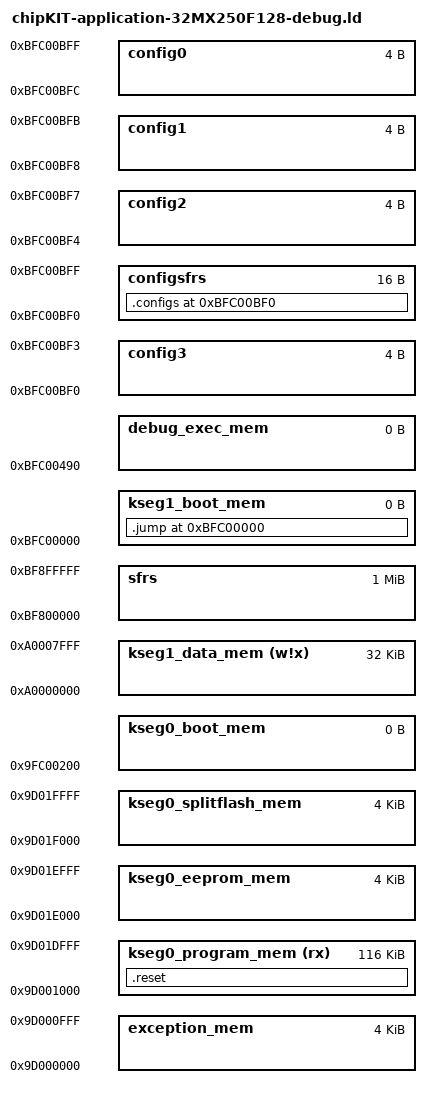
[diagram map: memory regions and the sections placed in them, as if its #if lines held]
/* Default linker script, for normal executables */
OUTPUT_FORMAT("elf32-tradlittlemips")
OUTPUT_ARCH(pic32mx)
ENTRY(_reset)
/*
 * Provide for a minimum stack and heap size
 * - _min_stack_size - represents the minimum space that must be made
 *                     available for the stack.  Can be overridden from
 *                     the command line using the linker's --defsym option.
 * - _min_heap_size  - represents the minimum space that must be made
 *                     available for the heap.  Can be overridden from
 *                     the command line using the linker's --defsym option.
 */
EXTERN (_min_stack_size _min_heap_size)
PROVIDE(_min_stack_size = 0x800) ;
PROVIDE(_min_heap_size = 0x800) ;

/*************************************************************************
 * Processor-specific object file.  Contains SFR definitions.
 *************************************************************************/
INPUT("processor.o")
OPTIONAL("libmchp_peripheral_32MX250F128D.a") 

/*************************************************************************
 * Memory Regions
 *
 * Memory regions without attributes cannot be used for orphaned sections.
 * Only sections specifically assigned to these regions can be allocated
 * into these regions.
 *************************************************************************/
MEMORY
{
  exception_mem              : ORIGIN = 0x9D000000, LENGTH = 0x1000
  kseg0_program_mem    (rx)  : ORIGIN = 0x9D001000, LENGTH = 0x1D000
  kseg0_eeprom_mem           : ORIGIN = 0x9D01E000, LENGTH = 0x1000
  kseg0_splitflash_mem       : ORIGIN = 0x9D01F000, LENGTH = 0x1000
  kseg0_boot_mem             : ORIGIN = 0x9FC00200, LENGTH = 0
  kseg1_boot_mem             : ORIGIN = 0xBFC00000, LENGTH = 0 
  debug_exec_mem             : ORIGIN = 0xBFC00490, LENGTH = 0
  config3                    : ORIGIN = 0xBFC00BF0, LENGTH = 0x4
  config2                    : ORIGIN = 0xBFC00BF4, LENGTH = 0x4
  config1                    : ORIGIN = 0xBFC00BF8, LENGTH = 0x4
  config0                    : ORIGIN = 0xBFC00BFC, LENGTH = 0x4
  kseg1_data_mem       (w!x) : ORIGIN = 0xA0000000, LENGTH = 0x8000
  sfrs                       : ORIGIN = 0xBF800000, LENGTH = 0x100000
  configsfrs                 : ORIGIN = 0xBFC00BF0, LENGTH = 0x10
}

/*************************************************************************
 * Memory Address Equates
 *************************************************************************/
_ebase_address  	    = ORIGIN(exception_mem);
_IMAGE_PTR_TABLE       	= _ebase_address + 0x0F8;
_IMAGE_HEADER_ADDR      = _ebase_address + 0x0FC;
_GEN_EXCPT_ADDR         = _ebase_address + 0x180;
_RESET_ADDR             = ORIGIN(kseg0_program_mem);
_EEPROM_ADDR            = ORIGIN(kseg0_eeprom_mem);
_BEV_EXCPT_ADDR         = 0xBFC00380;
_DBG_EXCPT_ADDR         = 0xBFC00480;
_DBG_CODE_ADDR          = ORIGIN(debug_exec_mem);

/*************************************************************************
 *  Bootloader program directives.
 *  
 * _IMAGE_TYPE
 *
 *  image type:
 */
     
_imageReserved                      = 0x00000000 ;
_imageMPIDE                         = 0x00000001 ;  /* This is a normal MPIDE sketch                                                                                                    */
_imageBootFlashBootloader           = 0x00000002 ;  /* This is a boot flash bootloader                                                                                                  */
_imageProgramFlashBootloader        = 0x00000004 ;  /* This is a program flash bootloader                                                                                               */
_imageSplitFlashBootloader          = 0x00000008 ;  /* This has bootloader code in both boot and program flash                                                                          */

 /*
 *  Instructions for the bootloader
 */
                                                                       
_imageFullFlashEraseLess4KEEProm    = 0x00010000 ;  /* The original bootloader method of erasing all of program flash except the last 4K reserved for eeprom                            */
_imageJustInTimeFlashErase          = 0x00020000 ;  /* Only flash pages written too needed by the sketch is erased                                                                      */
_imageLinkerSpecifiedFlashErase     = 0x00040000 ;  /* The linker defines the flash range to erase                                                                                      */
_imageFullFlashErase                = 0x00080000 ;  /* All of flash is erased                                                                                                           */
_imageExecutionJumpAddress          = 0x01000000 ;  /* the bootloader will jump to the execution jump address immediately after programming                                             */
_imageExecutionJumpToFirstInFlash   = 0x02000000 ;  /* the bootloader will jump to the first sketch loaded in flash ignoring the execution jump address immediately after programming   */
 
/*  
 * _IMAGE_FLASH_SIZE 
 *
 *      Typically _imageJustInTimeFlashErase is selected to just erase the pages
 *      of flash that code is written too; thus leaving all other flash pages untouched.
 *  
 *      If _imageLinkerSpecifiedFlashErase set, then the range
 *      starting from _ebase_address for _IMAGE_FLASH_SIZE bytes are erased.
 *
 *      If _imageFullFlashErase is specified, than the whole flash
 *      as known by the bootloader will be erased. This will erase eeprom as well
 *
 *      if _imageFullFlashEraseLess4KEEProm is set, all of flash less the last 4K is
 *      erased, this is the old default. This bit could be set to make a program flash bootloader
 *      erasing everything but the old flash. If NOTHING is set, this will be the default as this is the old behavior.
 *  
 *  _JUMP_ADDR
 *  
 *      This is the address that the bootloader will jump to start execution
 *      of the sketch. This is almost always _RESET_ADDR.
 *
 *      However, you can specify an alternate entry execution point for example
 *      if you have alternate starup code that, say, shared
 *      the runtime with other sketches or needed some kind of specific handling
 *
 *      Immediately after programming (avrdude upload) the bootloader will typically
 *      jump to the just loaded sketch, no matter where it was loaded in flash.
 *      _imageExecutionJumpToFirstInFlash will tell the bootloader to jump to the first
 *      sketch in flash even if the just loaded one is not at the beginning of flash.
 *      This is useful when programming sketches in slots of flash and then always
 *      jumping to the program-flash loader (vector sketch) as if the board was just reset.
 *      This bit does not effect jumping to a sketch already in flash after reset.
 *      As of today, after reset, the first program in flash will always be jumped to.
 *
 *************************************************************************/
 _IMAGE_TYPE            = _imageMPIDE | _imageJustInTimeFlashErase | _imageExecutionJumpAddress;
 _IMAGE_FLASH_SIZE      = LENGTH(exception_mem) + LENGTH(kseg0_program_mem);
_JUMP_ADDR              = _RESET_ADDR;

SECTIONS
{
#if defined(__DEBUG_D)
  /* Jump from reset vector */
  .jump ORIGIN(kseg1_boot_mem): {
    LONG(0x3C1F9D00)  /* lui ra 0x9d00 */
    LONG(0x37FF1000)  /* ori ra 0x1000 */
    LONG(0x03E00008)  /* jr ra */
    LONG(0x00000000)  /* nop */
  } > kseg1_boot_mem
#else
  /* Insert bootloader */
  .jump ORIGIN(kseg1_boot_mem): {
    LONG(0x401A6000)	/* 0x1FC00000 */
    LONG(0x7F5A04C0)	/* 0x1FC00004 */
    LONG(0x13400006)	/* 0x1FC00008 */
    LONG(0x401A6000)	/* 0x1FC0000C */
    LONG(0x3C1BFFBF)	/* 0x1FC00010 */
    LONG(0x377BFFFF)	/* 0x1FC00014 */
    LONG(0x35BD024)		/* 0x1FC00018 */
    LONG(0x409A6000)	/* 0x1FC0001C */
    LONG(0x42000018)	/* 0x1FC00020 */
    LONG(0x3C1DA000)	/* 0x1FC00024 */
    LONG(0x27BD3FF8)	/* 0x1FC00028 */
    LONG(0x3C1CA001)	/* 0x1FC0002C */
    LONG(0x279C85F0)	/* 0x1FC00030 */
    LONG(0x40096002)	/* 0x1FC00034 */
    LONG(0x1205820)		/* 0x1FC00038 */
    LONG(0x7D2A1E80)	/* 0x1FC0003C */
    LONG(0x7D494984)	/* 0x1FC00040 */
    LONG(0x40896002)	/* 0x1FC00044 */
    LONG(0xC0)			/* 0x1FC00048 */
    LONG(0x41DCE000)	/* 0x1FC0004C */
    LONG(0x408B6002)	/* 0x1FC00050 */
    LONG(0x3C08A000)	/* 0x1FC00054 */
    LONG(0x25080628)	/* 0x1FC00058 */
    LONG(0x3C09A000)	/* 0x1FC0005C */
    LONG(0x25290840)	/* 0x1FC00060 */
    LONG(0x10000006)	/* 0x1FC00064 */
    LONG(0x0)			/* 0x1FC00068 */
    LONG(0xAD000000)	/* 0x1FC0006C */
    LONG(0xAD000004)	/* 0x1FC00070 */
    LONG(0xAD000008)	/* 0x1FC00074 */
    LONG(0xAD00000C)	/* 0x1FC00078 */
    LONG(0x25080010)	/* 0x1FC0007C */
    LONG(0x109082B)		/* 0x1FC00080 */
    LONG(0x1420FFF9)	/* 0x1FC00084 */
    LONG(0x0)			/* 0x1FC00088 */
    LONG(0x3C089FC0)	/* 0x1FC0008C */
    LONG(0x25080A84)	/* 0x1FC00090 */
    LONG(0x8D090000)	/* 0x1FC00094 */
    LONG(0x11200018)	/* 0x1FC00098 */
    LONG(0x25080004)	/* 0x1FC0009C */
    LONG(0x8D0A0000)	/* 0x1FC000A0 */
    LONG(0x25080004)	/* 0x1FC000A4 */
    LONG(0x8D0B0000)	/* 0x1FC000A8 */
    LONG(0x11600009)	/* 0x1FC000AC */
    LONG(0x25080004)	/* 0x1FC000B0 */
    LONG(0x910C0000)	/* 0x1FC000B4 */
    LONG(0x254AFFFF)	/* 0x1FC000B8 */
    LONG(0x25080001)	/* 0x1FC000BC */
    LONG(0xA12C0000)	/* 0x1FC000C0 */
    LONG(0x1540FFFB)	/* 0x1FC000C4 */
    LONG(0x25290001)	/* 0x1FC000C8 */
    LONG(0x10000005)	/* 0x1FC000CC */
    LONG(0x0)			/* 0x1FC000D0 */
    LONG(0xA1200000)	/* 0x1FC000D4 */
    LONG(0x254AFFFF)	/* 0x1FC000D8 */
    LONG(0x1540FFFD)	/* 0x1FC000DC */
    LONG(0x25290001)	/* 0x1FC000E0 */
    LONG(0x25080003)	/* 0x1FC000E4 */
    LONG(0x240AFFFC)	/* 0x1FC000E8 */
    LONG(0x1484024)		/* 0x1FC000EC */
    LONG(0x8D090000)	/* 0x1FC000F0 */
    LONG(0x1520FFE7)	/* 0x1FC000F4 */
    LONG(0x0)			/* 0x1FC000F8 */
    LONG(0x3C09BFC0)	/* 0x1FC000FC */
    LONG(0x25290000)	/* 0x1FC00100 */
    LONG(0x40897801)	/* 0x1FC00104 */
    LONG(0x30840000)	/* 0x1FC00108 */
    LONG(0x30A50000)	/* 0x1FC0010C */
    LONG(0x3C089FC0)	/* 0x1FC00110 */
    LONG(0x25080BB8)	/* 0x1FC00114 */
    LONG(0x1000008)		/* 0x1FC00118 */
    LONG(0x0)			/* 0x1FC0011C */
    LONG(0xFFFFFFFF)	/* 0x1FC00120 */
    LONG(0xFFFFFFFF)	/* 0x1FC00124 */
    LONG(0xFFFFFFFF)	/* 0x1FC00128 */
    LONG(0xFFFFFFFF)	/* 0x1FC0012C */
    LONG(0xFFFFFFFF)	/* 0x1FC00130 */
    LONG(0xFFFFFFFF)	/* 0x1FC00134 */
    LONG(0xFFFFFFFF)	/* 0x1FC00138 */
    LONG(0xFFFFFFFF)	/* 0x1FC0013C */
    LONG(0xFFFFFFFF)	/* 0x1FC00140 */
    LONG(0xFFFFFFFF)	/* 0x1FC00144 */
    LONG(0xFFFFFFFF)	/* 0x1FC00148 */
    LONG(0xFFFFFFFF)	/* 0x1FC0014C */
    LONG(0xFFFFFFFF)	/* 0x1FC00150 */
    LONG(0xFFFFFFFF)	/* 0x1FC00154 */
    LONG(0xFFFFFFFF)	/* 0x1FC00158 */
    LONG(0xFFFFFFFF)	/* 0x1FC0015C */
    LONG(0xFFFFFFFF)	/* 0x1FC00160 */
    LONG(0xFFFFFFFF)	/* 0x1FC00164 */
    LONG(0xFFFFFFFF)	/* 0x1FC00168 */
    LONG(0xFFFFFFFF)	/* 0x1FC0016C */
    LONG(0xFFFFFFFF)	/* 0x1FC00170 */
    LONG(0xFFFFFFFF)	/* 0x1FC00174 */
    LONG(0xFFFFFFFF)	/* 0x1FC00178 */
    LONG(0xFFFFFFFF)	/* 0x1FC0017C */
    LONG(0xFFFFFFFF)	/* 0x1FC00180 */
    LONG(0xFFFFFFFF)	/* 0x1FC00184 */
    LONG(0xFFFFFFFF)	/* 0x1FC00188 */
    LONG(0xFFFFFFFF)	/* 0x1FC0018C */
    LONG(0xFFFFFFFF)	/* 0x1FC00190 */
    LONG(0xFFFFFFFF)	/* 0x1FC00194 */
    LONG(0xFFFFFFFF)	/* 0x1FC00198 */
    LONG(0xFFFFFFFF)	/* 0x1FC0019C */
    LONG(0xFFFFFFFF)	/* 0x1FC001A0 */
    LONG(0xFFFFFFFF)	/* 0x1FC001A4 */
    LONG(0xFFFFFFFF)	/* 0x1FC001A8 */
    LONG(0xFFFFFFFF)	/* 0x1FC001AC */
    LONG(0xFFFFFFFF)	/* 0x1FC001B0 */
    LONG(0xFFFFFFFF)	/* 0x1FC001B4 */
    LONG(0xFFFFFFFF)	/* 0x1FC001B8 */
    LONG(0xFFFFFFFF)	/* 0x1FC001BC */
    LONG(0xFFFFFFFF)	/* 0x1FC001C0 */
    LONG(0xFFFFFFFF)	/* 0x1FC001C4 */
    LONG(0xFFFFFFFF)	/* 0x1FC001C8 */
    LONG(0xFFFFFFFF)	/* 0x1FC001CC */
    LONG(0xFFFFFFFF)	/* 0x1FC001D0 */
    LONG(0xFFFFFFFF)	/* 0x1FC001D4 */
    LONG(0xFFFFFFFF)	/* 0x1FC001D8 */
    LONG(0xFFFFFFFF)	/* 0x1FC001DC */
    LONG(0xFFFFFFFF)	/* 0x1FC001E0 */
    LONG(0xFFFFFFFF)	/* 0x1FC001E4 */
    LONG(0xFFFFFFFF)	/* 0x1FC001E8 */
    LONG(0xFFFFFFFF)	/* 0x1FC001EC */
    LONG(0xFFFFFFFF)	/* 0x1FC001F0 */
    LONG(0xFFFFFFFF)	/* 0x1FC001F4 */
    LONG(0xFFFFFFFF)	/* 0x1FC001F8 */
    LONG(0xFFFFFFFF)	/* 0x1FC001FC */
    LONG(0x444CF0F0)	/* 0x1FC00200 */
    LONG(0x44A0F100)	/* 0x1FC00204 */
    LONG(0xEBA3B30D)	/* 0x1FC00208 */
    LONG(0x9A406115)	/* 0x1FC0020C */
    LONG(0x251242A1)	/* 0x1FC00210 */
    LONG(0xED4C6D03)	/* 0x1FC00214 */
    LONG(0x42A72D0F)	/* 0x1FC00218 */
    LONG(0xEBA34D39)	/* 0x1FC0021C */
    LONG(0xAAAE610B)	/* 0x1FC00220 */
    LONG(0x3360AA6F)	/* 0x1FC00224 */
    LONG(0xEBAD3360)	/* 0x1FC00228 */
    LONG(0x5B01EB8E)	/* 0x1FC0022C */
    LONG(0xEB6B6778)	/* 0x1FC00230 */
    LONG(0xEA6CE820)	/* 0x1FC00234 */
    LONG(0x6A00E820)	/* 0x1FC00238 */
    LONG(0x9D01F000)	/* 0x1FC0023C */
    LONG(0x27BDFFF8)	/* 0x1FC00240 */
    LONG(0xAFBF0004)	/* 0x1FC00244 */
    LONG(0x7CA5E000)	/* 0x1FC00248 */
    LONG(0x3C02BF81)	/* 0x1FC0024C */
    LONG(0xAC45F420)	/* 0x1FC00250 */
    LONG(0x3C02BF81)	/* 0x1FC00254 */
    LONG(0xAC46F430)	/* 0x1FC00258 */
    LONG(0x7CC6E000)	/* 0x1FC0025C */
    LONG(0x3C02BF81)	/* 0x1FC00260 */
    LONG(0xAC46F440)	/* 0x1FC00264 */
    LONG(0x34844000)	/* 0x1FC00268 */
    LONG(0x3C02BF81)	/* 0x1FC0026C */
    LONG(0xAC44F400)	/* 0x1FC00270 */
    LONG(0x40024800)	/* 0x1FC00274 */
    LONG(0x3C03BF81)	/* 0x1FC00278 */
    LONG(0x40044800)	/* 0x1FC0027C */
    LONG(0x822023)		/* 0x1FC00280 */
    LONG(0x2C840090)	/* 0x1FC00284 */
    LONG(0x1480FFFC)	/* 0x1FC00288 */
    LONG(0x3C04AA99)	/* 0x1FC0028C */
    LONG(0x3C02BF81)	/* 0x1FC00290 */
    LONG(0x24846655)	/* 0x1FC00294 */
    LONG(0xAC44F410)	/* 0x1FC00298 */
    LONG(0x3C045566)	/* 0x1FC0029C */
    LONG(0x348499AA)	/* 0x1FC002A0 */
    LONG(0xAC44F410)	/* 0x1FC002A4 */
    LONG(0x34048000)	/* 0x1FC002A8 */
    LONG(0x3C02BF81)	/* 0x1FC002AC */
    LONG(0xAC44F408)	/* 0x1FC002B0 */
    LONG(0x8C62F400)	/* 0x1FC002B4 */
    LONG(0x30428000)	/* 0x1FC002B8 */
    LONG(0x1440FFFD)	/* 0x1FC002BC */
    LONG(0x0)			/* 0x1FC002C0 */
    LONG(0x40034800)	/* 0x1FC002C4 */
    LONG(0x40024800)	/* 0x1FC002C8 */
    LONG(0x431023)		/* 0x1FC002CC */
    LONG(0x2C42000C)	/* 0x1FC002D0 */
    LONG(0x1440FFFC)	/* 0x1FC002D4 */
    LONG(0x3C02BF81)	/* 0x1FC002D8 */
    LONG(0x24034000)	/* 0x1FC002DC */
    LONG(0xAC43F404)	/* 0x1FC002E0 */
    LONG(0x8FBF0004)	/* 0x1FC002E4 */
    LONG(0x3E00008)		/* 0x1FC002E8 */
    LONG(0x27BD0008)	/* 0x1FC002EC */
    LONG(0xF40064F6)	/* 0x1FC002F0 */
    LONG(0xEA4B6A00)	/* 0x1FC002F4 */
    LONG(0xEF4C67E4)	/* 0x1FC002F8 */
    LONG(0xED4C4DFF)	/* 0x1FC002FC */
    LONG(0x4D00F400)	/* 0x1FC00300 */
    LONG(0xB018D504)	/* 0x1FC00304 */
    LONG(0xB218E88C)	/* 0x1FC00308 */
    LONG(0x3002E041)	/* 0x1FC0030C */
    LONG(0xB217300A)	/* 0x1FC00310 */
    LONG(0x9204E041)	/* 0x1FC00314 */
    LONG(0x6021EF43)	/* 0x1FC00318 */
    LONG(0xF400A040)	/* 0x1FC0031C */
    LONG(0x2A1A4760)	/* 0x1FC00320 */
    LONG(0x69016A05)	/* 0x1FC00324 */
    LONG(0x6787E92B)	/* 0x1FC00328 */
    LONG(0x6004EC6A)	/* 0x1FC0032C */
    LONG(0xE9AC9CA0)	/* 0x1FC00330 */
    LONG(0x17FA4C04)	/* 0x1FC00334 */
    LONG(0x240C4181)	/* 0x1FC00338 */
    LONG(0x6C04F008)	/* 0x1FC0033C */
    LONG(0x6E0067A7)	/* 0x1FC00340 */
    LONG(0x1E1FD205)	/* 0x1FC00344 */
    LONG(0xD3060090)	/* 0x1FC00348 */
    LONG(0x4AFF9205)	/* 0x1FC0034C */
    LONG(0x2AEB9306)	/* 0x1FC00350 */
    LONG(0xC0406A01)	/* 0x1FC00354 */
    LONG(0x480167E3)	/* 0x1FC00358 */
    LONG(0x647617DC)	/* 0x1FC0035C */
    LONG(0x6500E8A0)	/* 0x1FC00360 */
    LONG(0x1FFFFC00)	/* 0x1FC00364 */
    LONG(0xE3000000)	/* 0x1FC00368 */
    LONG(0xA0000940)	/* 0x1FC0036C */
    LONG(0x672464F5)	/* 0x1FC00370 */
    LONG(0x67466765)	/* 0x1FC00374 */
    LONG(0x680067E4)	/* 0x1FC00378 */
    LONG(0x6011E84A)	/* 0x1FC0037C */
    LONG(0xE4F1E333)	/* 0x1FC00380 */
    LONG(0x46819CC0)	/* 0x1FC00384 */
    LONG(0xF0082409)	/* 0x1FC00388 */
    LONG(0x67A76C01)	/* 0x1FC0038C */
    LONG(0x1E1FD205)	/* 0x1FC00390 */
    LONG(0xD3040090)	/* 0x1FC00394 */
    LONG(0x92059304)	/* 0x1FC00398 */
    LONG(0x48014F04)	/* 0x1FC0039C */
    LONG(0x647517ED)	/* 0x1FC003A0 */
    LONG(0x6500E8A0)	/* 0x1FC003A4 */
    LONG(0x181A64E3)	/* 0x1FC003A8 */
    LONG(0x671C7E03)	/* 0x1FC003AC */
    LONG(0x6A00F400)	/* 0x1FC003B0 */
    LONG(0xDB40B329)	/* 0x1FC003B4 */
    LONG(0xDB40B329)	/* 0x1FC003B8 */
    LONG(0x989CF010)	/* 0x1FC003BC */
    LONG(0x801A1F)		/* 0x1FC003C0 */
    LONG(0x2A036500)	/* 0x1FC003C4 */
    LONG(0x984CF030)	/* 0x1FC003C8 */
    LONG(0xF070EAC0)	/* 0x1FC003CC */
    LONG(0xEB11A074)	/* 0x1FC003D0 */
    LONG(0xAA8A230D)	/* 0x1FC003D4 */
    LONG(0x3360AA6B)	/* 0x1FC003D8 */
    LONG(0xEB8D3360)	/* 0x1FC003DC */
    LONG(0xEB8CB420)	/* 0x1FC003E0 */
    LONG(0xB4202305)	/* 0x1FC003E4 */
    LONG(0x801A1F)		/* 0x1FC003E8 */
    LONG(0x22076500)	/* 0x1FC003EC */
    LONG(0xAA6DAA8C)	/* 0x1FC003F0 */
    LONG(0x33603360)	/* 0x1FC003F4 */
    LONG(0xF030EB8D)	/* 0x1FC003F8 */
    LONG(0xAA80D86C)	/* 0x1FC003FC */
    LONG(0x3360AA61)	/* 0x1FC00400 */
    LONG(0xEB8D3360)	/* 0x1FC00404 */
    LONG(0x61DE5B3C)	/* 0x1FC00408 */
    LONG(0xAA7BAA9A)	/* 0x1FC0040C */
    LONG(0x33603360)	/* 0x1FC00410 */
    LONG(0x6790EB8D)	/* 0x1FC00414 */
    LONG(0x4C10F010)	/* 0x1FC00418 */
    LONG(0xED6344AC)	/* 0x1FC0041C */
    LONG(0xAABC61D3)	/* 0x1FC00420 */
    LONG(0x3240AA5D)	/* 0x1FC00424 */
    LONG(0xEAAD3240)	/* 0x1FC00428 */
    LONG(0x61015A09)	/* 0x1FC0042C */
    LONG(0xE4736A08)	/* 0x1FC00430 */
    LONG(0x6001EC43)	/* 0x1FC00434 */
    LONG(0xF0506744)	/* 0x1FC00438 */
    LONG(0x6C00D85C)	/* 0x1FC0043C */
    LONG(0x60C2EC4A)	/* 0x1FC00440 */
    LONG(0xF05067B0)	/* 0x1FC00444 */
    LONG(0xE4B54D1C)	/* 0x1FC00448 */
    LONG(0xE395A5C0)	/* 0x1FC0044C */
    LONG(0x4C01C5C0)	/* 0x1FC00450 */
    LONG(0x650017F5)	/* 0x1FC00454 */
    LONG(0xBF886034)	/* 0x1FC00458 */
    LONG(0xBF886018)	/* 0x1FC0045C */
    LONG(0x2000000)		/* 0x1FC00460 */
    LONG(0x9D000000)	/* 0x1FC00464 */
    LONG(0xF0D0675C)	/* 0x1FC00468 */
    LONG(0x2308A266)	/* 0x1FC0046C */
    LONG(0xA258F0B0)	/* 0x1FC00470 */
    LONG(0x64C32205)	/* 0x1FC00474 */
    LONG(0x7C4F181A)	/* 0x1FC00478 */
    LONG(0x64436500)	/* 0x1FC0047C */
    LONG(0x6500E8A0)	/* 0x1FC00480 */
    LONG(0x671C64FD)	/* 0x1FC00484 */
    LONG(0xB508F4C0)	/* 0x1FC00488 */
    LONG(0x67509D60)	/* 0x1FC0048C */
    LONG(0x4A1CF050)	/* 0x1FC00490 */
    LONG(0xF4C0DA61)	/* 0x1FC00494 */
    LONG(0x6A00B300)	/* 0x1FC00498 */
    LONG(0xF4A0DB40)	/* 0x1FC0049C */
    LONG(0xDB80B41C)	/* 0x1FC004A0 */
    LONG(0xB418F4A0)	/* 0x1FC004A4 */
    LONG(0xF4A0DB80)	/* 0x1FC004A8 */
    LONG(0xABC0B318)	/* 0x1FC004AC */
    LONG(0x6C01F004)	/* 0x1FC004B0 */
    LONG(0xECCCEC8B)	/* 0x1FC004B4 */
    LONG(0xF4A0CB80)	/* 0x1FC004B8 */
    LONG(0xDB40B30C)	/* 0x1FC004BC */
    LONG(0xB308F4A0)	/* 0x1FC004C0 */
    LONG(0xF4A0DB40)	/* 0x1FC004C4 */
    LONG(0xDB40B308)	/* 0x1FC004C8 */
    LONG(0xB204F4A0)	/* 0x1FC004CC */
    LONG(0x6B09AA80)	/* 0x1FC004D0 */
    LONG(0xEB8CEB6B)	/* 0x1FC004D4 */
    LONG(0xF400CA60)	/* 0x1FC004D8 */
    LONG(0xF4806B00)	/* 0x1FC004DC */
    LONG(0xDA60B218)	/* 0x1FC004E0 */
    LONG(0xB214F480)	/* 0x1FC004E4 */
    LONG(0x33629A60)	/* 0x1FC004E8 */
    LONG(0xB210F480)	/* 0x1FC004EC */
    LONG(0xEA4F9A40)	/* 0x1FC004F0 */
    LONG(0x67585A01)	/* 0x1FC004F4 */
    LONG(0x67987201)	/* 0x1FC004F8 */
    LONG(0xF480EB8C)	/* 0x1FC004FC */
    LONG(0x9A80B204)	/* 0x1FC00500 */
    LONG(0x4A016AFF)	/* 0x1FC00504 */
    LONG(0x67C5EC4C)	/* 0x1FC00508 */
    LONG(0x240D6A01)	/* 0x1FC0050C */
    LONG(0xB414F460)	/* 0x1FC00510 */
    LONG(0xED4C9CA0)	/* 0x1FC00514 */
    LONG(0x9CA02D08)	/* 0x1FC00518 */
    LONG(0xEDEC6F80)	/* 0x1FC0051C */
    LONG(0x9C802D04)	/* 0x1FC00520 */
    LONG(0xEC4E349A)	/* 0x1FC00524 */
    LONG(0xEA6CEA8C)	/* 0x1FC00528 */
    LONG(0xC044F070)	/* 0x1FC0052C */
    LONG(0x4C016CFF)	/* 0x1FC00530 */
    LONG(0xB314F440)	/* 0x1FC00534 */
    LONG(0x6B00DB80)	/* 0x1FC00538 */
    LONG(0x2203DE60)	/* 0x1FC0053C */
    LONG(0xEA1A1F)		/* 0x1FC00540 */
    LONG(0x1E1F6500)	/* 0x1FC00544 */
    LONG(0x65000153)	/* 0x1FC00548 */
    LONG(0x40024800)	/* 0x1FC0054C */
    LONG(0x77F00156)	/* 0x1FC00550 */
    LONG(0x0)			/* 0x1FC00554 */
    LONG(0xF0706500)	/* 0x1FC00558 */
    LONG(0xF070D84C)	/* 0x1FC0055C */
    LONG(0x181AD848)	/* 0x1FC00560 */
    LONG(0x65007E36)	/* 0x1FC00564 */
    LONG(0xB404F420)	/* 0x1FC00568 */
    LONG(0x7C95181A)	/* 0x1FC0056C */
    LONG(0x1E1F6500)	/* 0x1FC00570 */
    LONG(0x6500015E)	/* 0x1FC00574 */
    LONG(0x40024800)	/* 0x1FC00578 */
    LONG(0x77F00161)	/* 0x1FC0057C */
    LONG(0x0)			/* 0x1FC00580 */
    LONG(0xF0706500)	/* 0x1FC00584 */
    LONG(0xF070D850)	/* 0x1FC00588 */
    LONG(0xF070A0B5)	/* 0x1FC0058C */
    LONG(0xE2F398E8)	/* 0x1FC00590 */
    LONG(0xED66B3FF)	/* 0x1FC00594 */
    LONG(0x6106EC63)	/* 0x1FC00598 */
    LONG(0x6C00F400)	/* 0x1FC0059C */
    LONG(0xDB80B3FD)	/* 0x1FC005A0 */
    LONG(0xD848F070)	/* 0x1FC005A4 */
    LONG(0xA054F070)	/* 0x1FC005A8 */
    LONG(0x2AC8EA11)	/* 0x1FC005AC */
    LONG(0xA024F070)	/* 0x1FC005B0 */
    LONG(0x181A29C5)	/* 0x1FC005B4 */
    LONG(0x65007CD3)	/* 0x1FC005B8 */
    LONG(0xA048F050)	/* 0x1FC005BC */
    LONG(0xF05022D8)	/* 0x1FC005C0 */
    LONG(0xB2F59880)	/* 0x1FC005C4 */
    LONG(0xB7F5A262)	/* 0x1FC005C8 */
    LONG(0xC560E795)	/* 0x1FC005CC */
    LONG(0xF05044C2)	/* 0x1FC005D0 */
    LONG(0xC521D8C0)	/* 0x1FC005D4 */
    LONG(0x650A7311)	/* 0x1FC005D8 */
    LONG(0xF1206727)	/* 0x1FC005DC */
    LONG(0x5B12600E)	/* 0x1FC005E0 */
    LONG(0x7302602C)	/* 0x1FC005E4 */
    LONG(0x5B03606D)	/* 0x1FC005E8 */
    LONG(0x6A016012)	/* 0x1FC005EC */
    LONG(0xF160EB4E)	/* 0x1FC005F0 */
    LONG(0xF0702B12)	/* 0x1FC005F4 */
    LONG(0x6A01C064)	/* 0x1FC005F8 */
    LONG(0xC055F070)	/* 0x1FC005FC */
    LONG(0xC078F050)	/* 0x1FC00600 */
    LONG(0x6A08E7D9)	/* 0x1FC00604 */
    LONG(0x44C3C640)	/* 0x1FC00608 */
    LONG(0x6A00E6F9)	/* 0x1FC0060C */
    LONG(0x7303104E)	/* 0x1FC00610 */
    LONG(0x7306605D)	/* 0x1FC00614 */
    LONG(0x611FF140)	/* 0x1FC00618 */
    LONG(0xF600A263)	/* 0x1FC0061C */
    LONG(0xA2843360)	/* 0x1FC00620 */
    LONG(0x34803480)	/* 0x1FC00624 */
    LONG(0xA286EB8D)	/* 0x1FC00628 */
    LONG(0xA245EB8D)	/* 0x1FC0062C */
    LONG(0xEB4D3240)	/* 0x1FC00630 */
    LONG(0xF0103364)	/* 0x1FC00634 */
    LONG(0xE3AD98B8)	/* 0x1FC00638 */
    LONG(0x731410BD)	/* 0x1FC0063C */
    LONG(0x601DF0A0)	/* 0x1FC00640 */
    LONG(0x600D5B15)	/* 0x1FC00644 */
    LONG(0xF1407313)	/* 0x1FC00648 */
    LONG(0xA2636106)	/* 0x1FC0064C */
    LONG(0xA2843360)	/* 0x1FC00650 */
    LONG(0x43C3EB8D)	/* 0x1FC00654 */
    LONG(0xEC8B6C04)	/* 0x1FC00658 */
    LONG(0x6783EE8C)	/* 0x1FC0065C */
    LONG(0x6F1D1070)	/* 0x1FC00660 */
    LONG(0x273DEF6E)	/* 0x1FC00664 */
    LONG(0xF1207348)	/* 0x1FC00668 */
    LONG(0xA2636116)	/* 0x1FC0066C */
    LONG(0xA2E4652B)	/* 0x1FC00670 */
    LONG(0xA2E5650F)	/* 0x1FC00674 */
    LONG(0x656AA246)	/* 0x1FC00678 */
    LONG(0x32606768)	/* 0x1FC0067C */
    LONG(0x336033E0)	/* 0x1FC00680 */
    LONG(0x6769EA6D)	/* 0x1FC00684 */
    LONG(0x676BEA6D)	/* 0x1FC00688 */
    LONG(0x3360F600)	/* 0x1FC0068C */
    LONG(0xF030EA6D)	/* 0x1FC00690 */
    LONG(0xE1D9D85C)	/* 0x1FC00694 */
    LONG(0xC6406749)	/* 0x1FC00698 */
    LONG(0xC5636768)	/* 0x1FC0069C */
    LONG(0x4C06C5E4)	/* 0x1FC006A0 */
    LONG(0xD880F050)	/* 0x1FC006A4 */
    LONG(0xC585678B)	/* 0x1FC006A8 */
    LONG(0xB3BD1116)	/* 0x1FC006AC */
    LONG(0x8360E26D)	/* 0x1FC006B0 */
    LONG(0xC560E655)	/* 0x1FC006B4 */
    LONG(0x2BF94A01)	/* 0x1FC006B8 */
    LONG(0xF0504C0B)	/* 0x1FC006BC */
    LONG(0x110BD880)	/* 0x1FC006C0 */
    LONG(0xB4B8A263)	/* 0x1FC006C4 */
    LONG(0xA244E46D)	/* 0x1FC006C8 */
    LONG(0x1105C340)	/* 0x1FC006CC */
    LONG(0xF0504C03)	/* 0x1FC006D0 */
    LONG(0xE7D9D880)	/* 0x1FC006D4 */
    LONG(0xB3B3A243)	/* 0x1FC006D8 */
    LONG(0xA240E349)	/* 0x1FC006DC */
    LONG(0xE1D910AC)	/* 0x1FC006E0 */
    LONG(0xA2C6C6E0)	/* 0x1FC006E4 */
    LONG(0x4465C5C3)	/* 0x1FC006E8 */
    LONG(0xD860F050)	/* 0x1FC006EC */
    LONG(0x7630C5E4)	/* 0x1FC006F0 */
    LONG(0x610F4C06)	/* 0x1FC006F4 */
    LONG(0x2A05A248)	/* 0x1FC006F8 */
    LONG(0xD880F050)	/* 0x1FC006FC */
    LONG(0x6A50E16D)	/* 0x1FC00700 */
    LONG(0x72011014)	/* 0x1FC00704 */
    LONG(0xD880F050)	/* 0x1FC00708 */
    LONG(0x6A49E16D)	/* 0x1FC0070C */
    LONG(0x6A43600E)	/* 0x1FC00710 */
    LONG(0x6746100C)	/* 0x1FC00714 */
    LONG(0xEDAB6D09)	/* 0x1FC00718 */
    LONG(0x7220EAAC)	/* 0x1FC0071C */
    LONG(0xD880F050)	/* 0x1FC00720 */
    LONG(0x6A00E16D)	/* 0x1FC00724 */
    LONG(0x6A016102)	/* 0x1FC00728 */
    LONG(0xC340EA4B)	/* 0x1FC0072C */
    LONG(0x9840F050)	/* 0x1FC00730 */
    LONG(0xF0504261)	/* 0x1FC00734 */
    LONG(0xE149D860)	/* 0x1FC00738 */
    LONG(0xC2606B00)	/* 0x1FC0073C */
    LONG(0xECC310CC)	/* 0x1FC00740 */
    LONG(0x67E86007)	/* 0x1FC00744 */
    LONG(0x6F01E795)	/* 0x1FC00748 */
    LONG(0xC5ECEFEB)	/* 0x1FC0074C */
    LONG(0x17F74C01)	/* 0x1FC00750 */
    LONG(0xA090F010)	/* 0x1FC00754 */
    LONG(0xF100241C)	/* 0x1FC00758 */
    LONG(0x61165E00)	/* 0x1FC0075C */
    LONG(0x9898F030)	/* 0x1FC00760 */
    LONG(0x6D1FF1E0)	/* 0x1FC00764 */
    LONG(0x2D10ED8C)	/* 0x1FC00768 */
    LONG(0x9A44F100)	/* 0x1FC0076C */
    LONG(0x250C42A1)	/* 0x1FC00770 */
    LONG(0x98F8F010)	/* 0x1FC00774 */
    LONG(0xED4CB58C)	/* 0x1FC00778 */
    LONG(0xD8B8F010)	/* 0x1FC0077C */
    LONG(0xE591E5F7)	/* 0x1FC00780 */
    LONG(0xD898F030)	/* 0x1FC00784 */
    LONG(0xD85CF010)	/* 0x1FC00788 */
    LONG(0xF0106A00)	/* 0x1FC0078C */
    LONG(0xF030C050)	/* 0x1FC00790 */
    LONG(0x67829858)	/* 0x1FC00794 */
    LONG(0xD315E655)	/* 0x1FC00798 */
    LONG(0xBC1A1F)		/* 0x1FC0079C */
    LONG(0xF030D614)	/* 0x1FC007A0 */
    LONG(0xB5829898)	/* 0x1FC007A4 */
    LONG(0x1A1F9614)	/* 0x1FC007A8 */
    LONG(0x36CA00DC)	/* 0x1FC007AC */
    LONG(0xF0309315)	/* 0x1FC007B0 */
    LONG(0xE26D9858)	/* 0x1FC007B4 */
    LONG(0xD878F030)	/* 0x1FC007B8 */
    LONG(0xF030108E)	/* 0x1FC007BC */
    LONG(0xA2839878)	/* 0x1FC007C0 */
    LONG(0xE4713480)	/* 0x1FC007C4 */
    LONG(0xEC4DA244)	/* 0x1FC007C8 */
    LONG(0xEB836743)	/* 0x1FC007CC */
    LONG(0xF400602D)	/* 0x1FC007D0 */
    LONG(0xEDAB6D00)	/* 0x1FC007D4 */
    LONG(0xB376ED4C)	/* 0x1FC007D8 */
    LONG(0xB776EB4C)	/* 0x1FC007DC */
    LONG(0x3362E3ED)	/* 0x1FC007E0 */
    LONG(0xB775336A)	/* 0x1FC007E4 */
    LONG(0xA360E76D)	/* 0x1FC007E8 */
    LONG(0xEBEE6F01)	/* 0x1FC007EC */
    LONG(0xF7C0EB6B)	/* 0x1FC007F0 */
    LONG(0xEB113363)	/* 0x1FC007F4 */
    LONG(0xF400652B)	/* 0x1FC007F8 */
    LONG(0x654D4D00)	/* 0x1FC007FC */
    LONG(0x6001ECA3)	/* 0x1FC00800 */
    LONG(0x6762654C)	/* 0x1FC00804 */
    LONG(0xE775E65F)	/* 0x1FC00808 */
    LONG(0x67AA650D)	/* 0x1FC0080C */
    LONG(0x600AEBA3)	/* 0x1FC00810 */
    LONG(0xE77DE1FD)	/* 0x1FC00814 */
    LONG(0xA3E0650F)	/* 0x1FC00818 */
    LONG(0xEFAD67A9)	/* 0x1FC0081C */
    LONG(0xC5E067A8)	/* 0x1FC00820 */
    LONG(0x17F04B01)	/* 0x1FC00824 */
    LONG(0x17D067C8)	/* 0x1FC00828 */
    LONG(0xD878F030)	/* 0x1FC0082C */
    LONG(0xF0504641)	/* 0x1FC00830 */
    LONG(0xE1D9D840)	/* 0x1FC00834 */
    LONG(0xC6406A00)	/* 0x1FC00838 */
    LONG(0xF010104E)	/* 0x1FC0083C */
    LONG(0x1A1F989C)	/* 0x1FC00840 */
    LONG(0x65000080)	/* 0x1FC00844 */
    LONG(0xB55D2A02)	/* 0x1FC00848 */
    LONG(0x4284103F)	/* 0x1FC0084C */
    LONG(0xF03067B0)	/* 0x1FC00850 */
    LONG(0x6E014D08)	/* 0x1FC00854 */
    LONG(0xDC1A1F)		/* 0x1FC00858 */
    LONG(0x9214D214)	/* 0x1FC0085C */
    LONG(0x4C094287)	/* 0x1FC00860 */
    LONG(0xF03067B0)	/* 0x1FC00864 */
    LONG(0x1A1F4D04)	/* 0x1FC00868 */
    LONG(0x6E0100DC)	/* 0x1FC0086C */
    LONG(0x42879214)	/* 0x1FC00870 */
    LONG(0x67B04C05)	/* 0x1FC00874 */
    LONG(0x4D00F030)	/* 0x1FC00878 */
    LONG(0xDC1A1F)		/* 0x1FC0087C */
    LONG(0x92146E01)	/* 0x1FC00880 */
    LONG(0x4C354287)	/* 0x1FC00884 */
    LONG(0xF01067B0)	/* 0x1FC00888 */
    LONG(0x1A1F4D14)	/* 0x1FC0088C */
    LONG(0x6E0100DC)	/* 0x1FC00890 */
    LONG(0xAA8A9214)	/* 0x1FC00894 */
    LONG(0x3360AA6B)	/* 0x1FC00898 */
    LONG(0xEB8D3360)	/* 0x1FC0089C */
    LONG(0xEC6CB448)	/* 0x1FC008A0 */
    LONG(0xB4482C17)	/* 0x1FC008A4 */
    LONG(0x240CEC6C)	/* 0x1FC008A8 */
    LONG(0xAA8FAA6E)	/* 0x1FC008AC */
    LONG(0x34803480)	/* 0x1FC008B0 */
    LONG(0xAA70EC6D)	/* 0x1FC008B4 */
    LONG(0x35A0AAB1)	/* 0x1FC008B8 */
    LONG(0xED6D35A0)	/* 0x1FC008BC */
    LONG(0x1005E595)	/* 0x1FC008C0 */
    LONG(0xEB4CB241)	/* 0x1FC008C4 */
    LONG(0xB54123C0)	/* 0x1FC008C8 */
    LONG(0x1A1FB441)	/* 0x1FC008CC */
    LONG(0x650000BC)	/* 0x1FC008D0 */
    LONG(0xF0706A01)	/* 0x1FC008D4 */
    LONG(0x6A1BC054)	/* 0x1FC008D8 */
    LONG(0xC75067FD)	/* 0x1FC008DC */
    LONG(0xA050F050)	/* 0x1FC008E0 */
    LONG(0xF050C751)	/* 0x1FC008E4 */
    LONG(0x33439840)	/* 0x1FC008E8 */
    LONG(0xC753C772)	/* 0x1FC008EC */
    LONG(0xC7546A0E)	/* 0x1FC008F0 */
    LONG(0x67436B00)	/* 0x1FC008F4 */
    LONG(0xE5510504)	/* 0x1FC008F8 */
    LONG(0xEB8EA480)	/* 0x1FC008FC */
    LONG(0x72054A01)	/* 0x1FC00900 */
    LONG(0xF05061F9)	/* 0x1FC00904 */
    LONG(0x6785C069)	/* 0x1FC00908 */
    LONG(0x11A1A1F)		/* 0x1FC0090C */
    LONG(0xF0506D05)	/* 0x1FC00910 */
    LONG(0xF05098A0)	/* 0x1FC00914 */
    LONG(0x6A00A089)	/* 0x1FC00918 */
    LONG(0xEBAE6762)	/* 0x1FC0091C */
    LONG(0xE14D2305)	/* 0x1FC00920 */
    LONG(0x4A01A360)	/* 0x1FC00924 */
    LONG(0x17F8EC6E)	/* 0x1FC00928 */
    LONG(0xC089F050)	/* 0x1FC0092C */
    LONG(0x1A1FB41B)	/* 0x1FC00930 */
    LONG(0xD315011A)	/* 0x1FC00934 */
    LONG(0xF0506790)	/* 0x1FC00938 */
    LONG(0x1A1F4C09)	/* 0x1FC0093C */
    LONG(0x6D01011A)	/* 0x1FC00940 */
    LONG(0xF0509315)	/* 0x1FC00944 */
    LONG(0xF050D860)	/* 0x1FC00948 */
    LONG(0x1611C068)	/* 0x1FC0094C */
    LONG(0xBF80F600)	/* 0x1FC00950 */
    LONG(0xBF80F230)	/* 0x1FC00954 */
    LONG(0xAA996655)	/* 0x1FC00958 */
    LONG(0x556699AA)	/* 0x1FC0095C */
    LONG(0xBF80F200)	/* 0x1FC00960 */
    LONG(0xBF886000)	/* 0x1FC00964 */
    LONG(0xBF886100)	/* 0x1FC00968 */
    LONG(0xBF886200)	/* 0x1FC0096C */
    LONG(0xBF80F200)	/* 0x1FC00970 */
    LONG(0xBF886014)	/* 0x1FC00974 */
    LONG(0xBF886020)	/* 0x1FC00978 */
    LONG(0x9D001000)	/* 0x1FC0097C */
    LONG(0xBF886030)	/* 0x1FC00980 */
    LONG(0xBF80F600)	/* 0x1FC00984 */
    LONG(0xBF886034)	/* 0x1FC00988 */
    LONG(0x9D01F2B5)	/* 0x1FC0098C */
    LONG(0x2DC6C0)		/* 0x1FC00990 */
    LONG(0xBF88603C)	/* 0x1FC00994 */
    LONG(0xA0000DBC)	/* 0x1FC00998 */
    LONG(0xA00009BC)	/* 0x1FC0099C */
    LONG(0x9FC00BC8)	/* 0x1FC009A0 */
    LONG(0xA0000840)	/* 0x1FC009A4 */
    LONG(0xFFFF0000)	/* 0x1FC009A8 */
    LONG(0xA0000DC8)	/* 0x1FC009AC */
    LONG(0x1FFFFC00)	/* 0x1FC009B0 */
    LONG(0xE3000000)	/* 0x1FC009B4 */
    LONG(0xA0000940)	/* 0x1FC009B8 */
    LONG(0x9D01E000)	/* 0x1FC009BC */
    LONG(0x20000)		/* 0x1FC009C0 */
    LONG(0x40000)		/* 0x1FC009C4 */
    LONG(0x80000)		/* 0x1FC009C8 */
    LONG(0x9D01F000)	/* 0x1FC009CC */
    LONG(0x9D000000)	/* 0x1FC009D0 */
    LONG(0xEC11675C)	/* 0x1FC009D4 */
    LONG(0xA269F050)	/* 0x1FC009D8 */
    LONG(0xF050EB8E)	/* 0x1FC009DC */
    LONG(0xF050C269)	/* 0x1FC009E0 */
    LONG(0x5D079AB4)	/* 0x1FC009E4 */
    LONG(0x35A86047)	/* 0x1FC009E8 */
    LONG(0xE5D5B624)	/* 0x1FC009EC */
    LONG(0xED809DA0)	/* 0x1FC009F0 */
    LONG(0x9FC00A11)	/* 0x1FC009F4 */
    LONG(0x9FC00A21)	/* 0x1FC009F8 */
    LONG(0x9FC00A29)	/* 0x1FC009FC */
    LONG(0x9FC00A33)	/* 0x1FC00A00 */
    LONG(0x9FC00A41)	/* 0x1FC00A04 */
    LONG(0x9FC00A4F)	/* 0x1FC00A08 */
    LONG(0x9FC00A6B)	/* 0x1FC00A0C */
    LONG(0x6103741B)	/* 0x1FC00A10 */
    LONG(0xF0506B01)	/* 0x1FC00A14 */
    LONG(0xF050DA74)	/* 0x1FC00A18 */
    LONG(0xE8A0C289)	/* 0x1FC00A1C */
    LONG(0xC290F050)	/* 0x1FC00A20 */
    LONG(0x10266B02)	/* 0x1FC00A24 */
    LONG(0xF0503480)	/* 0x1FC00A28 */
    LONG(0x6B03DA8C)	/* 0x1FC00A2C */
    LONG(0xF0501021)	/* 0x1FC00A30 */
    LONG(0xEB8D9A6C)	/* 0x1FC00A34 */
    LONG(0xDA6CF050)	/* 0x1FC00A38 */
    LONG(0x101A6B04)	/* 0x1FC00A3C */
    LONG(0xEC6E6B0E)	/* 0x1FC00A40 */
    LONG(0xF0502C16)	/* 0x1FC00A44 */
    LONG(0x6B05DA84)	/* 0x1FC00A48 */
    LONG(0xF0501013)	/* 0x1FC00A4C */
    LONG(0x45619AA4)	/* 0x1FC00A50 */
    LONG(0xDA64F050)	/* 0x1FC00A54 */
    LONG(0xE6B5B60A)	/* 0x1FC00A58 */
    LONG(0xF050C582)	/* 0x1FC00A5C */
    LONG(0xEB8E9A8C)	/* 0x1FC00A60 */
    LONG(0x6B062B09)	/* 0x1FC00A64 */
    LONG(0x2B031005)	/* 0x1FC00A68 */
    LONG(0xF0506B01)	/* 0x1FC00A6C */
    LONG(0x6B00C268)	/* 0x1FC00A70 */
    LONG(0xDA74F050)	/* 0x1FC00A74 */
    LONG(0x6500E8A0)	/* 0x1FC00A78 */
    LONG(0x9FC009F4)	/* 0x1FC00A7C */
    LONG(0xA0000DBC)	/* 0x1FC00A80 */
    LONG(0xA0000840)	/* 0x1FC00A84 */
    LONG(0x97C)			/* 0x1FC00A88 */
    LONG(0x0)			/* 0x1FC00A8C */
    LONG(0xA0000600)	/* 0x1FC00A90 */
    LONG(0x20)			/* 0x1FC00A94 */
    LONG(0x1)			/* 0x1FC00A98 */
    LONG(0x1)			/* 0x1FC00A9C */
    LONG(0x600)			/* 0x1FC00AA0 */
    LONG(0x9D000000)	/* 0x1FC00AA4 */
    LONG(0x9D000000)	/* 0x1FC00AA8 */
    LONG(0x330F0612)	/* 0x1FC00AAC */
    LONG(0x40003)		/* 0x1FC00AB0 */
    LONG(0x1000303)		/* 0x1FC00AB4 */
    LONG(0x9D001000)	/* 0x1FC00AB8 */
    LONG(0xA0000628)	/* 0x1FC00ABC */
    LONG(0x40)			/* 0x1FC00AC0 */
    LONG(0x0)			/* 0x1FC00AC4 */
    LONG(0xA00011BC)	/* 0x1FC00AC8 */
    LONG(0x470)			/* 0x1FC00ACC */
    LONG(0x0)			/* 0x1FC00AD0 */
    LONG(0xA0000668)	/* 0x1FC00AD4 */
    LONG(0x8)			/* 0x1FC00AD8 */
    LONG(0x0)			/* 0x1FC00ADC */
    LONG(0xA0000620)	/* 0x1FC00AE0 */
    LONG(0x8)			/* 0x1FC00AE4 */
    LONG(0x1)			/* 0x1FC00AE8 */
    LONG(0x1C200)		/* 0x1FC00AEC */
    LONG(0x80000)		/* 0x1FC00AF0 */
    LONG(0xA0001800)	/* 0x1FC00AF4 */
    LONG(0x200)			/* 0x1FC00AF8 */
    LONG(0x0)			/* 0x1FC00AFC */
    LONG(0xA0000670)	/* 0x1FC00B00 */
    LONG(0x38)			/* 0x1FC00B04 */
    LONG(0x0)			/* 0x1FC00B08 */
    LONG(0xA00006C0)	/* 0x1FC00B0C */
    LONG(0x180)			/* 0x1FC00B10 */
    LONG(0x0)			/* 0x1FC00B14 */
    LONG(0x0)			/* 0x1FC00B18 */
    LONG(0x22222222)	/* 0x1FC00B1C */
    LONG(0x22222222)	/* 0x1FC00B20 */
    LONG(0x4090304)		/* 0x1FC00B24 */
    LONG(0x770322)		/* 0x1FC00B28 */
    LONG(0x770077)		/* 0x1FC00B2C */
    LONG(0x63002E)		/* 0x1FC00B30 */
    LONG(0x750070)		/* 0x1FC00B34 */
    LONG(0x740073)		/* 0x1FC00B38 */
    LONG(0x630069)		/* 0x1FC00B3C */
    LONG(0x2E006B)		/* 0x1FC00B40 */
    LONG(0x6F0063)		/* 0x1FC00B44 */
    LONG(0x312006D)		/* 0x1FC00B48 */
    LONG(0x740053)		/* 0x1FC00B4C */
    LONG(0x35006B)		/* 0x1FC00B50 */
    LONG(0x300030)		/* 0x1FC00B54 */
    LONG(0x320076)		/* 0x1FC00B58 */
    LONG(0x65000302)	/* 0x1FC00B5C */
    LONG(0x430209)		/* 0x1FC00B60 */
    LONG(0x80000102)	/* 0x1FC00B64 */
    LONG(0x409FA)		/* 0x1FC00B68 */
    LONG(0x2020100)		/* 0x1FC00B6C */
    LONG(0x24050001)	/* 0x1FC00B70 */
    LONG(0x4011000)		/* 0x1FC00B74 */
    LONG(0x5060224)		/* 0x1FC00B78 */
    LONG(0x1000624)		/* 0x1FC00B7C */
    LONG(0x12405)		/* 0x1FC00B80 */
    LONG(0x81050701)	/* 0x1FC00B84 */
    LONG(0x10000803)	/* 0x1FC00B88 */
    LONG(0x10409)		/* 0x1FC00B8C */
    LONG(0xA02)			/* 0x1FC00B90 */
    LONG(0x82050700)	/* 0x1FC00B94 */
    LONG(0x4002)			/* 0x1FC00B98 */
    LONG(0x2030507)		/* 0x1FC00B9C */
    LONG(0x40)			/* 0x1FC00BA0 */
    LONG(0x1010112)		/* 0x1FC00BA4 */
    LONG(0x40000002)	/* 0x1FC00BA8 */
    LONG(0xA6620403)	/* 0x1FC00BAC */
    LONG(0x2010180)		/* 0x1FC00BB0 */
    LONG(0x65000103)	/* 0x1FC00BB4 */
    LONG(0x77F00121)	/* 0x1FC00BB8 */
    LONG(0x0)			/* 0x1FC00BBC */
    LONG(0x1000FFFF)	/* 0x1FC00BC0 */
    LONG(0x0)			/* 0x1FC00BC4 */
    LONG(0x354B5453)	/* 0x1FC00BC8 */
    LONG(0x325F3030)	/* 0x1FC00BCC */
    LONG(0x65000000)	/* 0x1FC00BD0 */
  } > kseg1_boot_mem

  .btl_pt2 ORIGIN(kseg0_splitflash_mem) : {
    LONG(0x671C64E3)	/* 0x1D01F000 */
    LONG(0xB312B211)	/* 0x1D01F004 */
    LONG(0xDA806C00)	/* 0x1D01F008 */
    LONG(0xEA6A4A04)	/* 0x1D01F00C */
    LONG(0xF0D061FB)	/* 0x1D01F010 */
    LONG(0x6DFFA08C)	/* 0x1D01F014 */
    LONG(0x181A6E00)	/* 0x1D01F018 */
    LONG(0x67E67CAE)	/* 0x1D01F01C */
    LONG(0xA085F0D0)	/* 0x1D01F020 */
    LONG(0x6E006DFF)	/* 0x1D01F024 */
    LONG(0x7CAE181A)	/* 0x1D01F028 */
    LONG(0xF0B067E6)	/* 0x1D01F02C */
    LONG(0x6D00A09C)	/* 0x1D01F030 */
    LONG(0x181AB607)	/* 0x1D01F034 */
    LONG(0x6F407CAE)	/* 0x1D01F038 */
    LONG(0x985CF070)	/* 0x1D01F03C */
    LONG(0x6463EAC0)	/* 0x1D01F040 */
    LONG(0x6500E8A0)	/* 0x1D01F044 */
    LONG(0xA00011BC)	/* 0x1D01F048 */
    LONG(0xA00011FC)	/* 0x1D01F04C */
    LONG(0xA00015EC)	/* 0x1D01F050 */
    LONG(0x674667FC)	/* 0x1D01F054 */
    LONG(0x7320A461)	/* 0x1D01F058 */
    LONG(0x7321600B)	/* 0x1D01F05C */
    LONG(0x73016016)	/* 0x1D01F060 */
    LONG(0xE5CD6112)	/* 0x1D01F064 */
    LONG(0x601CED6A)	/* 0x1D01F068 */
    LONG(0xC5806C00)	/* 0x1D01F06C */
    LONG(0x17FA4D01)	/* 0x1D01F070 */
    LONG(0xE54D6A00)	/* 0x1D01F074 */
    LONG(0x6767A380)	/* 0x1D01F078 */
    LONG(0x4B10F030)	/* 0x1D01F07C */
    LONG(0xC380E26D)	/* 0x1D01F080 */
    LONG(0x72074A01)	/* 0x1D01F084 */
    LONG(0xE82061F6)	/* 0x1D01F088 */
    LONG(0x6B006A00)	/* 0x1D01F08C */
    LONG(0xF0306787)	/* 0x1D01F090 */
    LONG(0xE3914C10)	/* 0x1D01F094 */
    LONG(0xE571A4C0)	/* 0x1D01F098 */
    LONG(0x4B01C4C0)	/* 0x1D01F09C */
    LONG(0x61F67307)	/* 0x1D01F0A0 */
    LONG(0x6500E8A0)	/* 0x1D01F0A4 */
    LONG(0x671C64F5)	/* 0x1D01F0A8 */
    LONG(0x2C18EC11)	/* 0x1D01F0AC */
    LONG(0xC099F070)	/* 0x1D01F0B0 */
    LONG(0xF0B06A01)	/* 0x1D01F0B4 */
    LONG(0x6725C058)	/* 0x1D01F0B8 */
    LONG(0xEAC2E1AB)	/* 0x1D01F0BC */
    LONG(0xA1806009)	/* 0x1D01F0C0 */
    LONG(0x1A1FD504)	/* 0x1D01F0C4 */
    LONG(0xD6050275)	/* 0x1D01F0C8 */
    LONG(0x96054901)	/* 0x1D01F0CC */
    LONG(0x17F49504)	/* 0x1D01F0D0 */
    LONG(0xA09CF0B0)	/* 0x1D01F0D4 */
    LONG(0xB6166D00)	/* 0x1D01F0D8 */
    LONG(0x10226F40)	/* 0x1D01F0DC */
    LONG(0xA05AF070)	/* 0x1D01F0E0 */
    LONG(0x3448B314)	/* 0x1D01F0E4 */
    LONG(0x6D00E391)	/* 0x1D01F0E8 */
    LONG(0x4A01DCA0)	/* 0x1D01F0EC */
    LONG(0xEA8C6C0F)	/* 0x1D01F0F0 */
    LONG(0xED1167A2)	/* 0x1D01F0F4 */
    LONG(0xC0BAF070)	/* 0x1D01F0F8 */
    LONG(0xE3CD3648)	/* 0x1D01F0FC */
    LONG(0x57019BE0)	/* 0x1D01F100 */
    LONG(0xF0706112)	/* 0x1D01F104 */
    LONG(0xED6EA07B)	/* 0x1D01F108 */
    LONG(0x4B012D04)	/* 0x1D01F10C */
    LONG(0xF070EB8C)	/* 0x1D01F110 */
    LONG(0x3358C07B)	/* 0x1D01F114 */
    LONG(0xF0D0E34B)	/* 0x1D01F118 */
    LONG(0x6D01A08C)	/* 0x1D01F11C */
    LONG(0xE659B606)	/* 0x1D01F120 */
    LONG(0x7CAE181A)	/* 0x1D01F124 */
    LONG(0x64756500)	/* 0x1D01F128 */
    LONG(0x6A00E820)	/* 0x1D01F12C */
    LONG(0xA00015EC)	/* 0x1D01F130 */
    LONG(0xA00011BC)	/* 0x1D01F134 */
    LONG(0xA00011FC)	/* 0x1D01F138 */
    LONG(0x671C64F5)	/* 0x1D01F13C */
    LONG(0xA046F0D0)	/* 0x1D01F140 */
    LONG(0xF070226C)	/* 0x1D01F144 */
    LONG(0x2A69A059)	/* 0x1D01F148 */
    LONG(0x45676725)	/* 0x1D01F14C */
    LONG(0x6A3F4B37)	/* 0x1D01F150 */
    LONG(0x2A01EB5B)	/* 0x1D01F154 */
    LONG(0xEB12E8E5)	/* 0x1D01F158 */
    LONG(0xF0704B01)	/* 0x1D01F15C */
    LONG(0xF070A0FA)	/* 0x1D01F160 */
    LONG(0x47C7A05B)	/* 0x1D01F164 */
    LONG(0xE65B4E09)	/* 0x1D01F168 */
    LONG(0xEEBA6D10)	/* 0x1D01F16C */
    LONG(0xE8E52D01)	/* 0x1D01F170 */
    LONG(0x2E01EE10)	/* 0x1D01F174 */
    LONG(0xEE6267C5)	/* 0x1D01F178 */
    LONG(0xD3046019)	/* 0x1D01F17C */
    LONG(0x7CD3181A)	/* 0x1D01F180 */
    LONG(0x9304D405)	/* 0x1D01F184 */
    LONG(0x17E99405)	/* 0x1D01F188 */
    LONG(0x676A67AB)	/* 0x1D01F18C */
    LONG(0x654DE575)	/* 0x1D01F190 */
    LONG(0x676F67A8)	/* 0x1D01F194 */
    LONG(0x676AE575)	/* 0x1D01F198 */
    LONG(0x67AFDBA0)	/* 0x1D01F19C */
    LONG(0xE1A7E4B1)	/* 0x1D01F1A0 */
    LONG(0x61277610)	/* 0x1D01F1A4 */
    LONG(0x6B0F4A01)	/* 0x1D01F1A8 */
    LONG(0x2127EA6C)	/* 0x1D01F1AC */
    LONG(0x656BB31D)	/* 0x1D01F1B0 */
    LONG(0x654D3548)	/* 0x1D01F1B4 */
    LONG(0x9BA0E3AD)	/* 0x1D01F1B8 */
    LONG(0x6B3F650D)	/* 0x1D01F1BC */
    LONG(0x65EBE3AF)	/* 0x1D01F1C0 */
    LONG(0x6001E963)	/* 0x1D01F1C4 */
    LONG(0x355865E9)	/* 0x1D01F1C8 */
    LONG(0xB317E557)	/* 0x1D01F1CC */
    LONG(0xE575658B)	/* 0x1D01F1D0 */
    LONG(0xE5756768)	/* 0x1D01F1D4 */
    LONG(0x676F652C)	/* 0x1D01F1D8 */
    LONG(0x65ABE56D)	/* 0x1D01F1DC */
    LONG(0xED6A676D)	/* 0x1D01F1E0 */
    LONG(0x676960D3)	/* 0x1D01F1E4 */
    LONG(0xC560A360)	/* 0x1D01F1E8 */
    LONG(0x67694D01)	/* 0x1D01F1EC */
    LONG(0x652B4B01)	/* 0x1D01F1F0 */
    LONG(0x29D817F5)	/* 0x1D01F1F4 */
    LONG(0xC05BF070)	/* 0x1D01F1F8 */
    LONG(0xF0701010)	/* 0x1D01F1FC */
    LONG(0x610DC05B)	/* 0x1D01F200 */
    LONG(0xE6FB36F8)	/* 0x1D01F204 */
    LONG(0x674B37E8)	/* 0x1D01F208 */
    LONG(0xF0D0E2FD)	/* 0x1D01F20C */
    LONG(0x6D01A08C)	/* 0x1D01F210 */
    LONG(0xE3D9676C)	/* 0x1D01F214 */
    LONG(0x7CAE181A)	/* 0x1D01F218 */
    LONG(0x64759FE0)	/* 0x1D01F21C */
    LONG(0x6500E8A0)	/* 0x1D01F220 */
    LONG(0xA00011BC)	/* 0x1D01F224 */
    LONG(0xA00011FC)	/* 0x1D01F228 */
    LONG(0x671C64E3)	/* 0x1D01F22C */
    LONG(0xA058F070)	/* 0x1D01F230 */
    LONG(0xF0B0220A)	/* 0x1D01F234 */
    LONG(0x6D00A09C)	/* 0x1D01F238 */
    LONG(0x181AB605)	/* 0x1D01F23C */
    LONG(0x6F407CAE)	/* 0x1D01F240 */
    LONG(0xF0706A00)	/* 0x1D01F244 */
    LONG(0x6463C058)	/* 0x1D01F248 */
    LONG(0x6500E8A0)	/* 0x1D01F24C */
    LONG(0xA00015EC)	/* 0x1D01F250 */
    LONG(0xB311B210)	/* 0x1D01F254 */
    LONG(0xDAA06D00)	/* 0x1D01F258 */
    LONG(0xEA6A4A04)	/* 0x1D01F25C */
    LONG(0x64C361FB)	/* 0x1D01F260 */
    LONG(0xF070675C)	/* 0x1D01F264 */
    LONG(0xB40DDA9C)	/* 0x1D01F268 */
    LONG(0xB60EB50D)	/* 0x1D01F26C */
    LONG(0x7DF6181A)	/* 0x1D01F270 */
    LONG(0xB40D6500)	/* 0x1D01F274 */
    LONG(0x7DFA181A)	/* 0x1D01F278 */
    LONG(0xB40C6D12)	/* 0x1D01F27C */
    LONG(0x7DFD181A)	/* 0x1D01F280 */
    LONG(0xB40B6D43)	/* 0x1D01F284 */
    LONG(0x7E00181A)	/* 0x1D01F288 */
    LONG(0x64436D3A)	/* 0x1D01F28C */
    LONG(0x6500E8A0)	/* 0x1D01F290 */
    LONG(0xA00011BC)	/* 0x1D01F294 */
    LONG(0xA00011FC)	/* 0x1D01F298 */
    LONG(0x9D01F001)	/* 0x1D01F29C */
    LONG(0x9D01F055)	/* 0x1D01F2A0 */
    LONG(0x9D01F0A9)	/* 0x1D01F2A4 */
    LONG(0x9FC00BA4)	/* 0x1D01F2A8 */
    LONG(0x9FC00B60)	/* 0x1D01F2AC */
    LONG(0x9FC00B24)	/* 0x1D01F2B0 */
    LONG(0x6500E8A0)	/* 0x1D01F2B4 */
    LONG(0xED1164B1)	/* 0x1D01F2B8 */
    LONG(0x602475FF)	/* 0x1D01F2BC */
    LONG(0x3394B11D)	/* 0x1D01F2C0 */
    LONG(0xE263329C)	/* 0x1D01F2C4 */
    LONG(0xA004E101)	/* 0x1D01F2C8 */
    LONG(0x6001E8E2)	/* 0x1D01F2CC */
    LONG(0x30A467F0)	/* 0x1D01F2D0 */
    LONG(0xE3B5E26F)	/* 0x1D01F2D4 */
    LONG(0xA142E1A5)	/* 0x1D01F2D8 */
    LONG(0x3388E049)	/* 0x1D01F2DC */
    LONG(0x324CE269)	/* 0x1D01F2E0 */
    LONG(0xF0B0677C)	/* 0x1D01F2E4 */
    LONG(0xE3499B74)	/* 0x1D01F2E8 */
    LONG(0xEE6CB313)	/* 0x1D01F2EC */
    LONG(0x9A60DAC1)	/* 0x1D01F2F0 */
    LONG(0x6B1FF3E0)	/* 0x1D01F2F4 */
    LONG(0x37E0EF6C)	/* 0x1D01F2F8 */
    LONG(0x6B8837E0)	/* 0x1D01F2FC */
    LONG(0xA160EF6D)	/* 0x1D01F300 */
    LONG(0xDAE0EF6D)	/* 0x1D01F304 */
    LONG(0x74022409)	/* 0x1D01F308 */
    LONG(0x7403600A)	/* 0x1D01F30C */
    LONG(0x7401600B)	/* 0x1D01F310 */
    LONG(0x6B1D610C)	/* 0x1D01F314 */
    LONG(0x1008B209)	/* 0x1D01F318 */
    LONG(0xB2096B0D)	/* 0x1D01F31C */
    LONG(0x6B1D1005)	/* 0x1D01F320 */
    LONG(0x1002B208)	/* 0x1D01F324 */
    LONG(0xB2086B1D)	/* 0x1D01F328 */
    LONG(0x6431DA60)	/* 0x1D01F32C */
    LONG(0x6500E8A0)	/* 0x1D01F330 */
    LONG(0xA00006C0)	/* 0x1D01F334 */
    LONG(0x1FFFFFFF)	/* 0x1D01F338 */
    LONG(0xBF885310)	/* 0x1D01F33C */
    LONG(0xBF885300)	/* 0x1D01F340 */
    LONG(0xBF885320)	/* 0x1D01F344 */
    LONG(0xBF885330)	/* 0x1D01F348 */
    LONG(0x671C64F5)	/* 0x1D01F34C */
    LONG(0x9854F0B0)	/* 0x1D01F350 */
    LONG(0x2207F220)	/* 0x1D01F354 */
    LONG(0xF440658A)	/* 0x1D01F358 */
    LONG(0x9940B114)	/* 0x1D01F35C */
    LONG(0xEA6C6B08)	/* 0x1D01F360 */
    LONG(0x2208F160)	/* 0x1D01F364 */
    LONG(0xB208F440)	/* 0x1D01F368 */
    LONG(0x314E9A40)	/* 0x1D01F36C */
    LONG(0x652B6B01)	/* 0x1D01F370 */
    LONG(0x344AE96C)	/* 0x1D01F374 */
    LONG(0x654CEC6C)	/* 0x1D01F378 */
    LONG(0xEB4C6BF0)	/* 0x1D01F37C */
    LONG(0xF4203373)	/* 0x1D01F380 */
    LONG(0x3574B214)	/* 0x1D01F384 */
    LONG(0x367C65CD)	/* 0x1D01F388 */
    LONG(0xE6BB650E)	/* 0x1D01F38C */
    LONG(0xE639656E)	/* 0x1D01F390 */
    LONG(0xA6E0E2D9)	/* 0x1D01F394 */
    LONG(0x67E2651F)	/* 0x1D01F398 */
    LONG(0x5C016798)	/* 0x1D01F39C */
    LONG(0x35B867B8)	/* 0x1D01F3A0 */
    LONG(0xA682C6A0)	/* 0x1D01F3A4 */
    LONG(0x67B85C01)	/* 0x1D01F3A8 */
    LONG(0x3668C6A2)	/* 0x1D01F3AC */
    LONG(0xE699678A)	/* 0x1D01F3B0 */
    LONG(0xE6993424)	/* 0x1D01F3B4 */
    LONG(0x67AC36CC)	/* 0x1D01F3B8 */
    LONG(0x9E20E5D9)	/* 0x1D01F3BC */
    LONG(0xED2C6D3C)	/* 0x1D01F3C0 */
    LONG(0x740D34AB)	/* 0x1D01F3C4 */
    LONG(0x611AF0C0)	/* 0x1D01F3C8 */
    LONG(0xB3FB9E81)	/* 0x1D01F3CC */
    LONG(0xB5FBEC6D)	/* 0x1D01F3D0 */
    LONG(0x6E219D60)	/* 0x1D01F3D4 */
    LONG(0xEBCCEECB)	/* 0x1D01F3D8 */
    LONG(0x8CC3DD60)	/* 0x1D01F3DC */
    LONG(0xE22D672B)	/* 0x1D01F3E0 */
    LONG(0xC3A667A9)	/* 0x1D01F3E4 */
    LONG(0xDB236738)	/* 0x1D01F3E8 */
    LONG(0xA4A0DB22)	/* 0x1D01F3EC */
    LONG(0x696065AD)	/* 0x1D01F3F0 */
    LONG(0x672A6549)	/* 0x1D01F3F4 */
    LONG(0xF080ED2C)	/* 0x1D01F3F8 */
    LONG(0x8CA12D19)	/* 0x1D01F3FC */
    LONG(0xA421654D)	/* 0x1D01F400 */
    LONG(0x615F7106)	/* 0x1D01F404 */
    LONG(0xC3466A09)	/* 0x1D01F408 */
    LONG(0x720132A3)	/* 0x1D01F40C */
    LONG(0xF0B06117)	/* 0x1D01F410 */
    LONG(0xEAC29848)	/* 0x1D01F414 */
    LONG(0x67C26001)	/* 0x1D01F418 */
    LONG(0x678E6768)	/* 0x1D01F41C */
    LONG(0xE74DE38B)	/* 0x1D01F420 */
    LONG(0x4A10DBC3)	/* 0x1D01F424 */
    LONG(0xF0B0E74D)	/* 0x1D01F428 */
    LONG(0x6A00988C)	/* 0x1D01F42C */
    LONG(0x603CEACA)	/* 0x1D01F430 */
    LONG(0xA520E455)	/* 0x1D01F434 */
    LONG(0xC520E355)	/* 0x1D01F438 */
    LONG(0x17F84A01)	/* 0x1D01F43C */
    LONG(0x61177202)	/* 0x1D01F440 */
    LONG(0x9840F0B0)	/* 0x1D01F444 */
    LONG(0x6001EAC2)	/* 0x1D01F448 */
    LONG(0x672867C2)	/* 0x1D01F44C */
    LONG(0xE16B676E)	/* 0x1D01F450 */
    LONG(0xDBC3E74D)	/* 0x1D01F454 */
    LONG(0xE74D4A10)	/* 0x1D01F458 */
    LONG(0x9884F0B0)	/* 0x1D01F45C */
    LONG(0xEACA6A00)	/* 0x1D01F460 */
    LONG(0xE4556023)	/* 0x1D01F464 */
    LONG(0xE355A520)	/* 0x1D01F468 */
    LONG(0x4A01C520)	/* 0x1D01F46C */
    LONG(0x720317F8)	/* 0x1D01F470 */
    LONG(0x67256117)	/* 0x1D01F474 */
    LONG(0x6549E911)	/* 0x1D01F478 */
    LONG(0x9858F090)	/* 0x1D01F47C */
    LONG(0xF090652A)	/* 0x1D01F480 */
    LONG(0x6B00989C)	/* 0x1D01F484 */
    LONG(0x67AA6743)	/* 0x1D01F488 */
    LONG(0xF160ED6A)	/* 0x1D01F48C */
    LONG(0x4B016014)	/* 0x1D01F490 */
    LONG(0xEA226729)	/* 0x1D01F494 */
    LONG(0x6008F160)	/* 0x1D01F498 */
    LONG(0xA520E455)	/* 0x1D01F49C */
    LONG(0x17F3E229)	/* 0x1D01F4A0 */
    LONG(0xEACE6E06)	/* 0x1D01F4A4 */
    LONG(0xDB432A01)	/* 0x1D01F4A8 */
    LONG(0x674E6728)	/* 0x1D01F4AC */
    LONG(0x45C7E157)	/* 0x1D01F4B0 */
    LONG(0xE7D94E09)	/* 0x1D01F4B4 */
    LONG(0x9F43E7BD)	/* 0x1D01F4B8 */
    LONG(0xEAE2A7E4)	/* 0x1D01F4BC */
    LONG(0x67E26034)	/* 0x1D01F4C0 */
    LONG(0x71011032)	/* 0x1D01F4C4 */
    LONG(0x67CD6111)	/* 0x1D01F4C8 */
    LONG(0xF0807602)	/* 0x1D01F4CC */
    LONG(0x67EA6105)	/* 0x1D01F4D0 */
    LONG(0x2F02F080)	/* 0x1D01F4D4 */
    LONG(0x6B0FAC82)	/* 0x1D01F4D8 */
    LONG(0x3474EB8C)	/* 0x1D01F4DC */
    LONG(0xE38F337C)	/* 0x1D01F4E0 */
    LONG(0xC2E0E269)	/* 0x1D01F4E4 */
    LONG(0x1078C2E1)	/* 0x1D01F4E8 */
    LONG(0x61047105)	/* 0x1D01F4EC */
    LONG(0xF09067AA)	/* 0x1D01F4F0 */
    LONG(0x1072C0A0)	/* 0x1D01F4F4 */
    LONG(0x61097109)	/* 0x1D01F4F8 */
    LONG(0x9848F0D0)	/* 0x1D01F4FC */
    LONG(0xF0D04A01)	/* 0x1D01F500 */
    LONG(0x67E9D848)	/* 0x1D01F504 */
    LONG(0xC0E6F0D0)	/* 0x1D01F508 */
    LONG(0x71081067)	/* 0x1D01F50C */
    LONG(0x6C096165)	/* 0x1D01F510 */
    LONG(0x6789C386)	/* 0x1D01F514 */
    LONG(0xC390DB83)	/* 0x1D01F518 */
    LONG(0x4E1067CB)	/* 0x1D01F51C */
    LONG(0xA3E4E659)	/* 0x1D01F520 */
    LONG(0x6001ECE2)	/* 0x1D01F524 */
    LONG(0x6C006F01)	/* 0x1D01F528 */
    LONG(0x105A6D01)	/* 0x1D01F52C */
    LONG(0x35FE67ED)	/* 0x1D01F530 */
    LONG(0x67EB2513)	/* 0x1D01F534 */
    LONG(0xE75D4F10)	/* 0x1D01F538 */
    LONG(0xD704D305)	/* 0x1D01F53C */
    LONG(0x9830F090)	/* 0x1D01F540 */
    LONG(0x67A7E940)	/* 0x1D01F544 */
    LONG(0x93056C09)	/* 0x1D01F548 */
    LONG(0xDB43C386)	/* 0x1D01F54C */
    LONG(0x6D016C00)	/* 0x1D01F550 */
    LONG(0x67C79704)	/* 0x1D01F554 */
    LONG(0x104467E2)	/* 0x1D01F558 */
    LONG(0xDBC32608)	/* 0x1D01F55C */
    LONG(0x4E1067CB)	/* 0x1D01F560 */
    LONG(0x67A46C00)	/* 0x1D01F564 */
    LONG(0xA3E4E2D9)	/* 0x1D01F568 */
    LONG(0x6790103B)	/* 0x1D01F56C */
    LONG(0x4C04F090)	/* 0x1D01F570 */
    LONG(0xF0906D00)	/* 0x1D01F574 */
    LONG(0xEB409870)	/* 0x1D01F578 */
    LONG(0x102E67C5)	/* 0x1D01F57C */
    LONG(0xED2CB590)	/* 0x1D01F580 */
    LONG(0x35A335A3)	/* 0x1D01F584 */
    LONG(0x2B44650D)	/* 0x1D01F588 */
    LONG(0xA2A69EA1)	/* 0x1D01F58C */
    LONG(0x2D2CED8E)	/* 0x1D01F590 */
    LONG(0x610D7409)	/* 0x1D01F594 */
    LONG(0x9AA26788)	/* 0x1D01F598 */
    LONG(0xDA62E4AD)	/* 0x1D01F59C */
    LONG(0xEBEA9AE3)	/* 0x1D01F5A0 */
    LONG(0x60026C00)	/* 0x1D01F5A4 */
    LONG(0x100C6D01)	/* 0x1D01F5A8 */
    LONG(0x67C467A4)	/* 0x1D01F5AC */
    LONG(0x67C81018)	/* 0x1D01F5B0 */
    LONG(0xE6ED9AE2)	/* 0x1D01F5B4 */
    LONG(0x9AE3DA62)	/* 0x1D01F5B8 */
    LONG(0x6006EBEA)	/* 0x1D01F5BC */
    LONG(0x67A46C00)	/* 0x1D01F5C0 */
    LONG(0xE679B680)	/* 0x1D01F5C4 */
    LONG(0x100CE77F)	/* 0x1D01F5C8 */
    LONG(0xF0906790)	/* 0x1D01F5CC */
    LONG(0xB57D4C04)	/* 0x1D01F5D0 */
    LONG(0x9830F090)	/* 0x1D01F5D4 */
    LONG(0x67C3E940)	/* 0x1D01F5D8 */
    LONG(0x6D016C00)	/* 0x1D01F5DC */
    LONG(0x67E667C4)	/* 0x1D01F5E0 */
    LONG(0x7CAE181A)	/* 0x1D01F5E4 */
    LONG(0x10236500)	/* 0x1D01F5E8 */
    LONG(0xA0A0F090)	/* 0x1D01F5EC */
    LONG(0xB4762506)	/* 0x1D01F5F0 */
    LONG(0xEAAD9C40)	/* 0x1D01F5F4 */
    LONG(0xF090DC40)	/* 0x1D01F5F8 */
    LONG(0x6A00C060)	/* 0x1D01F5FC */
    LONG(0x6A40C740)	/* 0x1D01F600 */
    LONG(0x6C00C741)	/* 0x1D01F604 */
    LONG(0x67D067A4)	/* 0x1D01F608 */
    LONG(0x4E04F090)	/* 0x1D01F60C */
    LONG(0x17E86F08)	/* 0x1D01F610 */
    LONG(0xA045F0D0)	/* 0x1D01F614 */
    LONG(0x230BEB4E)	/* 0x1D01F618 */
    LONG(0x6B099E41)	/* 0x1D01F61C */
    LONG(0x5C01EC6E)	/* 0x1D01F620 */
    LONG(0xB5656798)	/* 0x1D01F624 */
    LONG(0xF090ED4D)	/* 0x1D01F628 */
    LONG(0xEB40986C)	/* 0x1D01F62C */
    LONG(0x6A0867C8)	/* 0x1D01F630 */
    LONG(0xDC40B45E)	/* 0x1D01F634 */
    LONG(0x9D40B55D)	/* 0x1D01F638 */
    LONG(0xEA6C6B01)	/* 0x1D01F63C */
    LONG(0x2202F080)	/* 0x1D01F640 */
    LONG(0xF0B06A00)	/* 0x1D01F644 */
    LONG(0xF0D0C058)	/* 0x1D01F648 */
    LONG(0x6B00C046)	/* 0x1D01F64C */
    LONG(0xDA60B25E)	/* 0x1D01F650 */
    LONG(0x9A60B25A)	/* 0x1D01F654 */
    LONG(0xEB8D6C02)	/* 0x1D01F658 */
    LONG(0x9A60DA60)	/* 0x1D01F65C */
    LONG(0xEB8C4CFB)	/* 0x1D01F660 */
    LONG(0xF0B0DA60)	/* 0x1D01F664 */
    LONG(0xF1009854)	/* 0x1D01F668 */
    LONG(0xEA6A4260)	/* 0x1D01F66C */
    LONG(0x6C006004)	/* 0x1D01F670 */
    LONG(0x4A01C280)	/* 0x1D01F674 */
    LONG(0xB25517FA)	/* 0x1D01F678 */
    LONG(0x4A01B355)	/* 0x1D01F67C */
    LONG(0x6004EA6A)	/* 0x1D01F680 */
    LONG(0xF7FF6C00)	/* 0x1D01F684 */
    LONG(0x17F9C29E)	/* 0x1D01F688 */
    LONG(0xF0B0B34A)	/* 0x1D01F68C */
    LONG(0xA247984C)	/* 0x1D01F690 */
    LONG(0xF0B0C344)	/* 0x1D01F694 */
    LONG(0xF0B098E4)	/* 0x1D01F698 */
    LONG(0x6C0098C0)	/* 0x1D01F69C */
    LONG(0x6036ECC2)	/* 0x1D01F6A0 */
    LONG(0xA2A1E789)	/* 0x1D01F6A4 */
    LONG(0x612F7505)	/* 0x1D01F6A8 */
    LONG(0x7502A2A3)	/* 0x1D01F6AC */
    LONG(0xA2A26119)	/* 0x1D01F6B0 */
    LONG(0x210731BE)	/* 0x1D01F6B4 */
    LONG(0x6509690F)	/* 0x1D01F6B8 */
    LONG(0xED2C6728)	/* 0x1D01F6BC */
    LONG(0xC0ACF0D0)	/* 0x1D01F6C0 */
    LONG(0x690F1006)	/* 0x1D01F6C4 */
    LONG(0x67286509)	/* 0x1D01F6C8 */
    LONG(0xF0B0ED2C)	/* 0x1D01F6CC */
    LONG(0xA224C0BC)	/* 0x1D01F6D0 */
    LONG(0x31B46509)	/* 0x1D01F6D4 */
    LONG(0xE53735BC)	/* 0x1D01F6D8 */
    LONG(0x6728E3B5)	/* 0x1D01F6DC */
    LONG(0x1013C524)	/* 0x1D01F6E0 */
    LONG(0x61117503)	/* 0x1D01F6E4 */
    LONG(0x650DA2A2)	/* 0x1D01F6E8 */
    LONG(0x67286D0F)	/* 0x1D01F6EC */
    LONG(0xF0D0ED2C)	/* 0x1D01F6F0 */
    LONG(0xA224C0A5)	/* 0x1D01F6F4 */
    LONG(0x31B46509)	/* 0x1D01F6F8 */
    LONG(0xE53735BC)	/* 0x1D01F6FC */
    LONG(0x6728E3B5)	/* 0x1D01F700 */
    LONG(0x6901C524)	/* 0x1D01F704 */
    LONG(0xA240C525)	/* 0x1D01F708 */
    LONG(0x17C8E451)	/* 0x1D01F70C */
    LONG(0xB4276AFF)	/* 0x1D01F710 */
    LONG(0xB430DC40)	/* 0x1D01F714 */
    LONG(0x6D189C40)	/* 0x1D01F718 */
    LONG(0xDC40EAAD)	/* 0x1D01F71C */
    LONG(0xF090D305)	/* 0x1D01F720 */
    LONG(0xEDC098B4)	/* 0x1D01F724 */
    LONG(0x93056A00)	/* 0x1D01F728 */
    LONG(0x6A40C340)	/* 0x1D01F72C */
    LONG(0x6C00C341)	/* 0x1D01F730 */
    LONG(0x67D067A4)	/* 0x1D01F734 */
    LONG(0x4E04F090)	/* 0x1D01F738 */
    LONG(0x7CAE181A)	/* 0x1D01F73C */
    LONG(0x6A016F08)	/* 0x1D01F740 */
    LONG(0xDE40B61A)	/* 0x1D01F744 */
    LONG(0x9F40B719)	/* 0x1D01F748 */
    LONG(0xEA6C6B10)	/* 0x1D01F74C */
    LONG(0x6A00222A)	/* 0x1D01F750 */
    LONG(0xC058F0B0)	/* 0x1D01F754 */
    LONG(0xC046F0D0)	/* 0x1D01F758 */
    LONG(0x9C40B41E)	/* 0x1D01F75C */
    LONG(0xEDAB6D11)	/* 0x1D01F760 */
    LONG(0xDC40EAAC)	/* 0x1D01F764 */
    LONG(0x101DDF60)	/* 0x1D01F768 */
    LONG(0x676E6728)	/* 0x1D01F76C */
    LONG(0xE749E16B)	/* 0x1D01F770 */
    LONG(0xDA636B00)	/* 0x1D01F774 */
    LONG(0xE4491699)	/* 0x1D01F778 */
    LONG(0xEE82A280)	/* 0x1D01F77C */
    LONG(0x67866001)	/* 0x1D01F780 */
    LONG(0x67CE67A8)	/* 0x1D01F784 */
    LONG(0xE779E5CF)	/* 0x1D01F788 */
    LONG(0x4B10DE83)	/* 0x1D01F78C */
    LONG(0x6B00E779)	/* 0x1D01F790 */
    LONG(0xF69FEB8A)	/* 0x1D01F794 */
    LONG(0xE2756009)	/* 0x1D01F798 */
    LONG(0xE675A520)	/* 0x1D01F79C */
    LONG(0x4B01C520)	/* 0x1D01F7A0 */
    LONG(0x647517F7)	/* 0x1D01F7A4 */
    LONG(0x6500E8A0)	/* 0x1D01F7A8 */
    LONG(0xBF885200)	/* 0x1D01F7AC */
    LONG(0xBF885240)	/* 0x1D01F7B0 */
    LONG(0xA00006C0)	/* 0x1D01F7B4 */
    LONG(0xA0000000)	/* 0x1D01F7B8 */
    LONG(0xBF885250)	/* 0x1D01F7BC */
    LONG(0x3FF0000)		/* 0x1D01F7C0 */
    LONG(0xA00006D0)	/* 0x1D01F7C4 */
    LONG(0xBF885260)	/* 0x1D01F7C8 */
    LONG(0xA00006C1)	/* 0x1D01F7CC */
    LONG(0xA0000842)	/* 0x1D01F7D0 */
    LONG(0xBF885210)	/* 0x1D01F7D4 */
    LONG(0xF090675C)	/* 0x1D01F7D8 */
    LONG(0xF090DA94)	/* 0x1D01F7DC */
    LONG(0xF090DAB0)	/* 0x1D01F7E0 */
    LONG(0xE8A0DACC)	/* 0x1D01F7E4 */
    LONG(0xF0B0675C)	/* 0x1D01F7E8 */
    LONG(0xF0B0DA8C)	/* 0x1D01F7EC */
    LONG(0xE8A0DAA8)	/* 0x1D01F7F0 */
    LONG(0xF0B0675C)	/* 0x1D01F7F4 */
    LONG(0xF0B0DA84)	/* 0x1D01F7F8 */
    LONG(0xE8A0DAA0)	/* 0x1D01F7FC */
    LONG(0xF090675C)	/* 0x1D01F800 */
    LONG(0xF090DA9C)	/* 0x1D01F804 */
    LONG(0xE8A0DAB8)	/* 0x1D01F808 */
    LONG(0xF0B0675C)	/* 0x1D01F80C */
    LONG(0x2252A250)	/* 0x1D01F810 */
    LONG(0xF40064F5)	/* 0x1D01F814 */
    LONG(0xB2296B00)	/* 0x1D01F818 */
    LONG(0x6810DA60)	/* 0x1D01F81C */
    LONG(0x6B00F400)	/* 0x1D01F820 */
    LONG(0xDA60B227)	/* 0x1D01F824 */
    LONG(0x7E0C1C1A)	/* 0x1D01F828 */
    LONG(0x65006500)	/* 0x1D01F82C */
    LONG(0x40024800)	/* 0x1D01F830 */
    LONG(0x77407E0F)	/* 0x1D01F834 */
    LONG(0x0)			/* 0x1D01F838 */
    LONG(0xB1216500)	/* 0x1D01F83C */
    LONG(0x7CD3181A)	/* 0x1D01F840 */
    LONG(0x1C1AD204)	/* 0x1D01F844 */
    LONG(0x65007E13)	/* 0x1D01F848 */
    LONG(0x40034800)	/* 0x1D01F84C */
    LONG(0x77407E16)	/* 0x1D01F850 */
    LONG(0x0)			/* 0x1D01F854 */
    LONG(0x92046500)	/* 0x1D01F858 */
    LONG(0xB41AE34F)	/* 0x1D01F85C */
    LONG(0x60EEEC63)	/* 0x1D01F860 */
    LONG(0x28DC48FF)	/* 0x1D01F864 */
    LONG(0xDA00B218)	/* 0x1D01F868 */
    LONG(0xDA00B218)	/* 0x1D01F86C */
    LONG(0xA280B218)	/* 0x1D01F870 */
    LONG(0xEB6B6B02)	/* 0x1D01F874 */
    LONG(0xC260EB8C)	/* 0x1D01F878 */
    LONG(0x7E211C1A)	/* 0x1D01F87C */
    LONG(0x65006500)	/* 0x1D01F880 */
    LONG(0x40024800)	/* 0x1D01F884 */
    LONG(0x77407E24)	/* 0x1D01F888 */
    LONG(0x0)			/* 0x1D01F88C */
    LONG(0xF4006500)	/* 0x1D01F890 */
    LONG(0xD9606B00)	/* 0x1D01F894 */
    LONG(0x7E281C1A)	/* 0x1D01F898 */
    LONG(0x65006500)	/* 0x1D01F89C */
    LONG(0x40044800)	/* 0x1D01F8A0 */
    LONG(0x77407E2B)	/* 0x1D01F8A4 */
    LONG(0x0)			/* 0x1D01F8A8 */
    LONG(0xE4536500)	/* 0x1D01F8AC */
    LONG(0xEB83B309)	/* 0x1D01F8B0 */
    LONG(0x647560EE)	/* 0x1D01F8B4 */
    LONG(0x6500E8A0)	/* 0x1D01F8B8 */
    LONG(0xBF886034)	/* 0x1D01F8BC */
    LONG(0xBF88603C)	/* 0x1D01F8C0 */
    LONG(0x2DC6C0)		/* 0x1D01F8C4 */
    LONG(0xBF885250)	/* 0x1D01F8C8 */
    LONG(0xBF885070)	/* 0x1D01F8CC */
    LONG(0xBF885080)	/* 0x1D01F8D0 */
    LONG(0xB71B00)		/* 0x1D01F8D4 */
    LONG(0x67BC64A1)	/* 0x1D01F8D8 */
    LONG(0xF0B0B314)	/* 0x1D01F8DC */
    LONG(0xB414DD74)	/* 0x1D01F8E0 */
    LONG(0x6A01A4C0)	/* 0x1D01F8E4 */
    LONG(0xC4C0EE4D)	/* 0x1D01F8E8 */
    LONG(0xB4126E4A)	/* 0x1D01F8EC */
    LONG(0xB612DCC0)	/* 0x1D01F8F0 */
    LONG(0x34C2EE6C)	/* 0x1D01F8F4 */
    LONG(0x67046BFF)	/* 0x1D01F8F8 */
    LONG(0xB710E86C)	/* 0x1D01F8FC */
    LONG(0x3482DF00)	/* 0x1D01F900 */
    LONG(0xB70FEC6C)	/* 0x1D01F904 */
    LONG(0xF600DF80)	/* 0x1D01F908 */
    LONG(0xB40E36C2)	/* 0x1D01F90C */
    LONG(0xB40EDCC0)	/* 0x1D01F910 */
    LONG(0x6E84DC40)	/* 0x1D01F914 */
    LONG(0xDCC0B40D)	/* 0x1D01F918 */
    LONG(0xDC60B40D)	/* 0x1D01F91C */
    LONG(0xDB40B30D)	/* 0x1D01F920 */
    LONG(0xC550F0B0)	/* 0x1D01F924 */
    LONG(0xE8A06421)	/* 0x1D01F928 */
    LONG(0xA0001800)	/* 0x1D01F92C */
    LONG(0xBF885080)	/* 0x1D01F930 */
    LONG(0xBF8852B0)	/* 0x1D01F934 */
    LONG(0x1FFFFFFF)	/* 0x1D01F938 */
    LONG(0xBF885270)	/* 0x1D01F93C */
    LONG(0xBF8852C0)	/* 0x1D01F940 */
    LONG(0xBF8852D0)	/* 0x1D01F944 */
    LONG(0xBF885250)	/* 0x1D01F948 */
    LONG(0xBF885070)	/* 0x1D01F94C */
    LONG(0xBF885200)	/* 0x1D01F950 */
    LONG(0xBF885210)	/* 0x1D01F954 */
  } > kseg0_splitflash_mem
#endif

  .configs ORIGIN(configsfrs) :
  {
    LONG(0xFFFFFFF)	/* 0x1FC00BF0 */
    LONG(0xFFF979F9)	/* 0x1FC00BF4 */
    LONG(0xFF6A0D5B)	/* 0x1FC00BF8 */
    LONG(0x7FFFFFFB)	/* 0x1FC00BFC */
  } > configsfrs

  /* Boot Sections */
  .reset _RESET_ADDR :
  {
    KEEP(*(.reset))
  } > kseg0_program_mem
}

/* From here out every linker script is the same, so just include it */
/*INCLUDE "chipKIT-application-COMMON.ld"*/
